# ESP32-P4 register map
Vendor: ESPRESSIF SYSTEMS (SHANGHAI) CO., LTD.; Series: ESP32 P-Series; File version: 3
CPU: RV32IMAFC r0p0, little endian, no MPU, FPU, 0 interrupt priority bits
Address unit: 32 bits
Registers are 32-bit, read-write, reset 0x0 unless marked. A register's access mark holds for its fields unless they carry their own. Offsets are from the block's base; [hi:lo] are bit positions; {n}, {i} and the like mark numbered series.

## PMU — PMU Peripheral
Base 0x50115000
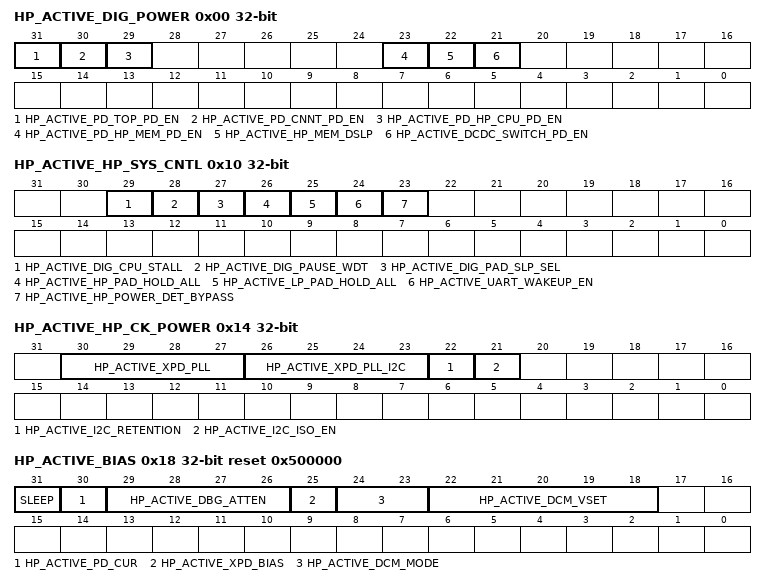
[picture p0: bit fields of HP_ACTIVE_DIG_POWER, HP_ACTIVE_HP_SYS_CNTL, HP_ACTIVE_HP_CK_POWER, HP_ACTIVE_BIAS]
0x00 HP_ACTIVE_DIG_POWER — need_des
  [31] HP_ACTIVE_PD_TOP_PD_EN — need_des
  [30] HP_ACTIVE_PD_CNNT_PD_EN — need_des
  [29] HP_ACTIVE_PD_HP_CPU_PD_EN — need_des
  [23] HP_ACTIVE_PD_HP_MEM_PD_EN — need_des
  [22] HP_ACTIVE_HP_MEM_DSLP — need_des
  [21] HP_ACTIVE_DCDC_SWITCH_PD_EN — need_des
0x04 HP_ACTIVE_ICG_HP_FUNC reset 0xFFFFFFFF — need_des
  [31:0] HP_ACTIVE_DIG_ICG_FUNC_EN
0x08 HP_ACTIVE_ICG_HP_APB reset 0xFFFFFFFF — need_des
  [31:0] HP_ACTIVE_DIG_ICG_APB_EN
0x0C HP_ACTIVE_ICG_MODEM — need_des
  [31:30] HP_ACTIVE_DIG_ICG_MODEM_CODE
0x10 HP_ACTIVE_HP_SYS_CNTL — need_des
  [29] HP_ACTIVE_DIG_CPU_STALL — need_des
  [28] HP_ACTIVE_DIG_PAUSE_WDT — need_des
  [27] HP_ACTIVE_DIG_PAD_SLP_SEL — need_des
  [26] HP_ACTIVE_HP_PAD_HOLD_ALL — need_des
  [25] HP_ACTIVE_LP_PAD_HOLD_ALL — need_des
  [24] HP_ACTIVE_UART_WAKEUP_EN — need_des
  [23] HP_ACTIVE_HP_POWER_DET_BYPASS — need_des
0x14 HP_ACTIVE_HP_CK_POWER — need_des
  [30:27] HP_ACTIVE_XPD_PLL — need_des
  [26:23] HP_ACTIVE_XPD_PLL_I2C — need_des
  [22] HP_ACTIVE_I2C_RETENTION — need_des
  [21] HP_ACTIVE_I2C_ISO_EN — need_des
0x18 HP_ACTIVE_BIAS reset 0x500000 — need_des
  [31] SLEEP — need_des
  [30] HP_ACTIVE_PD_CUR — need_des
  [29:26] HP_ACTIVE_DBG_ATTEN — need_des
  [25] HP_ACTIVE_XPD_BIAS — need_des
  [24:23] HP_ACTIVE_DCM_MODE — need_des
  [22:18] HP_ACTIVE_DCM_VSET — need_des
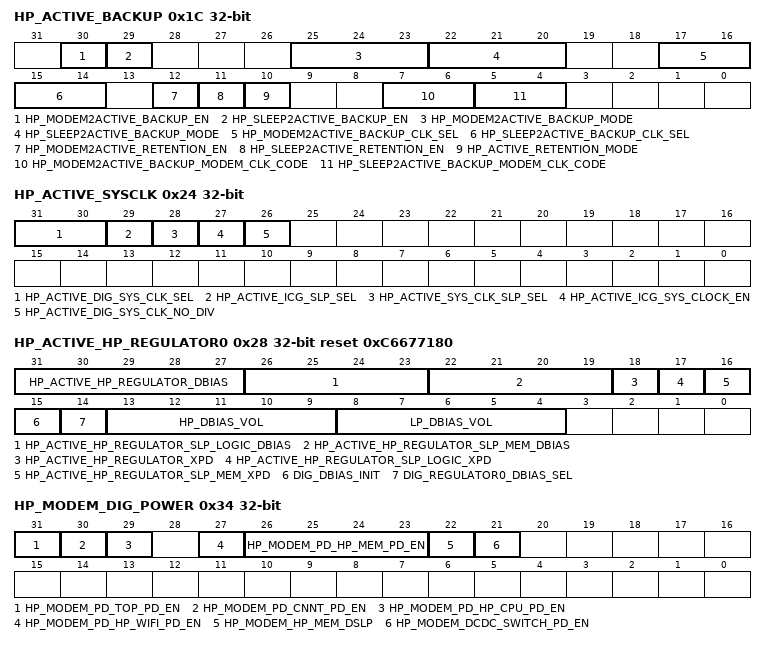
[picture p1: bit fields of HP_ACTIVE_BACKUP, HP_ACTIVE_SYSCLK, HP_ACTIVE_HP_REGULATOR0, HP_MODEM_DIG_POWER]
0x1C HP_ACTIVE_BACKUP — need_des
  [30] HP_MODEM2ACTIVE_BACKUP_EN — need_des
  [29] HP_SLEEP2ACTIVE_BACKUP_EN — need_des
  [25:23] HP_MODEM2ACTIVE_BACKUP_MODE — need_des
  [22:20] HP_SLEEP2ACTIVE_BACKUP_MODE — need_des
  [17:16] HP_MODEM2ACTIVE_BACKUP_CLK_SEL — need_des
  [15:14] HP_SLEEP2ACTIVE_BACKUP_CLK_SEL — need_des
  [12] HP_MODEM2ACTIVE_RETENTION_EN — need_des
  [11] HP_SLEEP2ACTIVE_RETENTION_EN — need_des
  [10] HP_ACTIVE_RETENTION_MODE — need_des
  [7:6] HP_MODEM2ACTIVE_BACKUP_MODEM_CLK_CODE — need_des
  [5:4] HP_SLEEP2ACTIVE_BACKUP_MODEM_CLK_CODE — need_des
0x20 HP_ACTIVE_BACKUP_CLK — need_des
  [31:0] HP_ACTIVE_BACKUP_ICG_FUNC_EN
0x24 HP_ACTIVE_SYSCLK — need_des
  [31:30] HP_ACTIVE_DIG_SYS_CLK_SEL — need_des
  [29] HP_ACTIVE_ICG_SLP_SEL — need_des
  [28] HP_ACTIVE_SYS_CLK_SLP_SEL — need_des
  [27] HP_ACTIVE_ICG_SYS_CLOCK_EN — need_des
  [26] HP_ACTIVE_DIG_SYS_CLK_NO_DIV — need_des
0x28 HP_ACTIVE_HP_REGULATOR0 access per field reset 0xC6677180 — need_des
  [31:27] HP_ACTIVE_HP_REGULATOR_DBIAS rw — need_des
  [26:23] HP_ACTIVE_HP_REGULATOR_SLP_LOGIC_DBIAS rw — need_des
  [22:19] HP_ACTIVE_HP_REGULATOR_SLP_MEM_DBIAS rw — need_des
  [18] HP_ACTIVE_HP_REGULATOR_XPD rw — need_des
  [17] HP_ACTIVE_HP_REGULATOR_SLP_LOGIC_XPD rw — need_des
  [16] HP_ACTIVE_HP_REGULATOR_SLP_MEM_XPD rw — need_des
  [15] DIG_DBIAS_INIT wo — need_des
  [14] DIG_REGULATOR0_DBIAS_SEL rw — need_des
  [13:9] HP_DBIAS_VOL ro — need_des
  [8:4] LP_DBIAS_VOL ro — need_des
0x2C HP_ACTIVE_HP_REGULATOR1 — need_des
  [31:26] HP_ACTIVE_HP_REGULATOR_DRV_B
0x30 HP_ACTIVE_XTAL reset 0x80000000 — need_des
  [31] HP_ACTIVE_XPD_XTAL
0x34 HP_MODEM_DIG_POWER access per field — need_des
  [31] HP_MODEM_PD_TOP_PD_EN wo — need_des
  [30] HP_MODEM_PD_CNNT_PD_EN wo — need_des
  [29] HP_MODEM_PD_HP_CPU_PD_EN wo — need_des
  [27] HP_MODEM_PD_HP_WIFI_PD_EN wo — need_des
  [26:23] HP_MODEM_PD_HP_MEM_PD_EN wo — need_des
  [22] HP_MODEM_HP_MEM_DSLP wo — need_des
  [21] HP_MODEM_DCDC_SWITCH_PD_EN rw — need_des
0x38 HP_MODEM_ICG_HP_FUNC wo — need_des
  [31:0] HP_MODEM_DIG_ICG_FUNC_EN
0x3C HP_MODEM_ICG_HP_APB wo — need_des
  [31:0] HP_MODEM_DIG_ICG_APB_EN
0x40 HP_MODEM_ICG_MODEM wo — need_des
  [31:30] HP_MODEM_DIG_ICG_MODEM_CODE
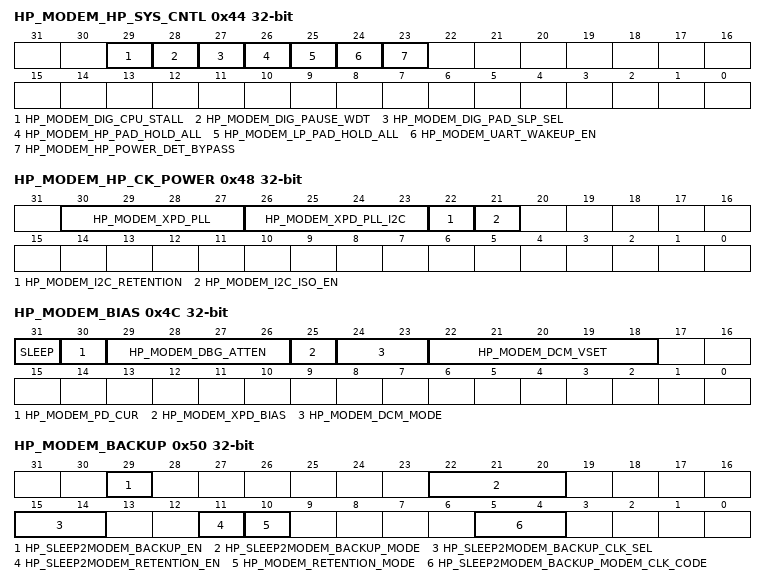
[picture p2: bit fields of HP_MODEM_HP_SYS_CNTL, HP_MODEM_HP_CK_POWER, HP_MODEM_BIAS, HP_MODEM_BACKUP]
0x44 HP_MODEM_HP_SYS_CNTL wo — need_des
  [29] HP_MODEM_DIG_CPU_STALL — need_des
  [28] HP_MODEM_DIG_PAUSE_WDT — need_des
  [27] HP_MODEM_DIG_PAD_SLP_SEL — need_des
  [26] HP_MODEM_HP_PAD_HOLD_ALL — need_des
  [25] HP_MODEM_LP_PAD_HOLD_ALL — need_des
  [24] HP_MODEM_UART_WAKEUP_EN — need_des
  [23] HP_MODEM_HP_POWER_DET_BYPASS — need_des
0x48 HP_MODEM_HP_CK_POWER wo — need_des
  [30:27] HP_MODEM_XPD_PLL — need_des
  [26:23] HP_MODEM_XPD_PLL_I2C — need_des
  [22] HP_MODEM_I2C_RETENTION — need_des
  [21] HP_MODEM_I2C_ISO_EN — need_des
0x4C HP_MODEM_BIAS wo — need_des
  [31] SLEEP — need_des
  [30] HP_MODEM_PD_CUR — need_des
  [29:26] HP_MODEM_DBG_ATTEN — need_des
  [25] HP_MODEM_XPD_BIAS — need_des
  [24:23] HP_MODEM_DCM_MODE — need_des
  [22:18] HP_MODEM_DCM_VSET — need_des
0x50 HP_MODEM_BACKUP wo — need_des
  [29] HP_SLEEP2MODEM_BACKUP_EN — need_des
  [22:20] HP_SLEEP2MODEM_BACKUP_MODE — need_des
  [15:14] HP_SLEEP2MODEM_BACKUP_CLK_SEL — need_des
  [11] HP_SLEEP2MODEM_RETENTION_EN — need_des
  [10] HP_MODEM_RETENTION_MODE — need_des
  [5:4] HP_SLEEP2MODEM_BACKUP_MODEM_CLK_CODE — need_des
0x54 HP_MODEM_BACKUP_CLK wo — need_des
  [31:0] HP_MODEM_BACKUP_ICG_FUNC_EN
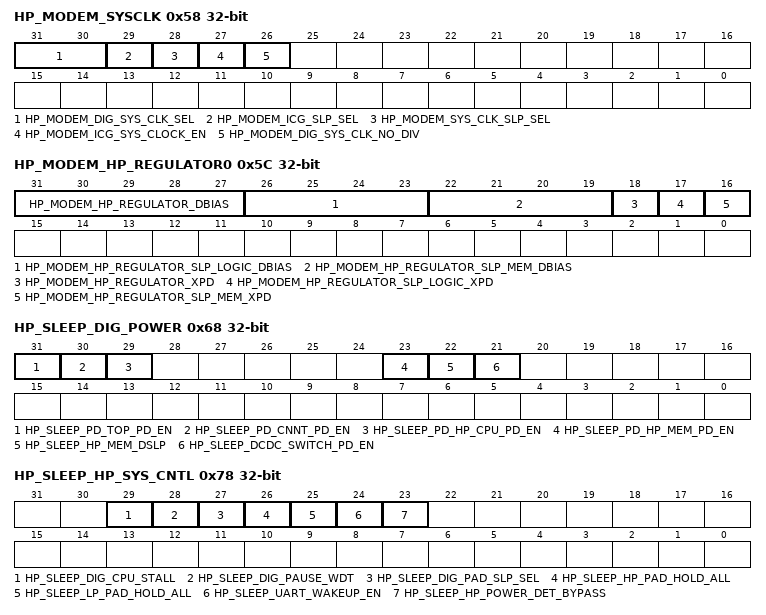
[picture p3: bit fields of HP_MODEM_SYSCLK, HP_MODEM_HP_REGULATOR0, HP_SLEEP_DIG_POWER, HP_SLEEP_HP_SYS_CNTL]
0x58 HP_MODEM_SYSCLK wo — need_des
  [31:30] HP_MODEM_DIG_SYS_CLK_SEL — need_des
  [29] HP_MODEM_ICG_SLP_SEL — need_des
  [28] HP_MODEM_SYS_CLK_SLP_SEL — need_des
  [27] HP_MODEM_ICG_SYS_CLOCK_EN — need_des
  [26] HP_MODEM_DIG_SYS_CLK_NO_DIV — need_des
0x5C HP_MODEM_HP_REGULATOR0 wo — need_des
  [31:27] HP_MODEM_HP_REGULATOR_DBIAS — need_des
  [26:23] HP_MODEM_HP_REGULATOR_SLP_LOGIC_DBIAS — need_des
  [22:19] HP_MODEM_HP_REGULATOR_SLP_MEM_DBIAS — need_des
  [18] HP_MODEM_HP_REGULATOR_XPD — need_des
  [17] HP_MODEM_HP_REGULATOR_SLP_LOGIC_XPD — need_des
  [16] HP_MODEM_HP_REGULATOR_SLP_MEM_XPD — need_des
0x60 HP_MODEM_HP_REGULATOR1 wo — need_des
  [31:8] HP_MODEM_HP_REGULATOR_DRV_B
0x64 HP_MODEM_XTAL wo — need_des
  [31] HP_MODEM_XPD_XTAL
0x68 HP_SLEEP_DIG_POWER — need_des
  [31] HP_SLEEP_PD_TOP_PD_EN — need_des
  [30] HP_SLEEP_PD_CNNT_PD_EN — need_des
  [29] HP_SLEEP_PD_HP_CPU_PD_EN — need_des
  [23] HP_SLEEP_PD_HP_MEM_PD_EN — need_des
  [22] HP_SLEEP_HP_MEM_DSLP — need_des
  [21] HP_SLEEP_DCDC_SWITCH_PD_EN — need_des
0x6C HP_SLEEP_ICG_HP_FUNC reset 0xFFFFFFFF — need_des
  [31:0] HP_SLEEP_DIG_ICG_FUNC_EN
0x70 HP_SLEEP_ICG_HP_APB reset 0xFFFFFFFF — need_des
  [31:0] HP_SLEEP_DIG_ICG_APB_EN
0x74 HP_SLEEP_ICG_MODEM — need_des
  [31:30] HP_SLEEP_DIG_ICG_MODEM_CODE
0x78 HP_SLEEP_HP_SYS_CNTL — need_des
  [29] HP_SLEEP_DIG_CPU_STALL — need_des
  [28] HP_SLEEP_DIG_PAUSE_WDT — need_des
  [27] HP_SLEEP_DIG_PAD_SLP_SEL — need_des
  [26] HP_SLEEP_HP_PAD_HOLD_ALL — need_des
  [25] HP_SLEEP_LP_PAD_HOLD_ALL — need_des
  [24] HP_SLEEP_UART_WAKEUP_EN — need_des
  [23] HP_SLEEP_HP_POWER_DET_BYPASS — need_des
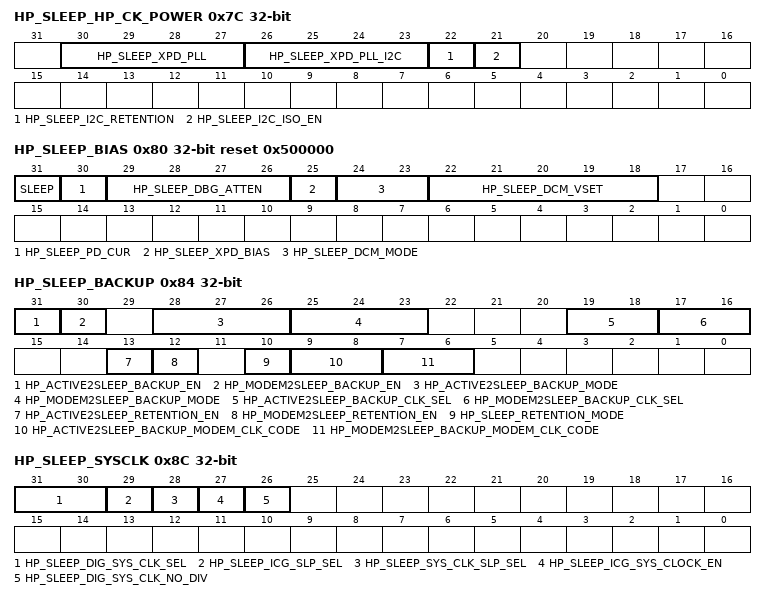
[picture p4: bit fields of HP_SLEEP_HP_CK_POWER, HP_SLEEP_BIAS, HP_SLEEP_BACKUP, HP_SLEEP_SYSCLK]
0x7C HP_SLEEP_HP_CK_POWER — need_des
  [30:27] HP_SLEEP_XPD_PLL — need_des
  [26:23] HP_SLEEP_XPD_PLL_I2C — need_des
  [22] HP_SLEEP_I2C_RETENTION — need_des
  [21] HP_SLEEP_I2C_ISO_EN — need_des
0x80 HP_SLEEP_BIAS reset 0x500000 — need_des
  [31] SLEEP — need_des
  [30] HP_SLEEP_PD_CUR — need_des
  [29:26] HP_SLEEP_DBG_ATTEN — need_des
  [25] HP_SLEEP_XPD_BIAS — need_des
  [24:23] HP_SLEEP_DCM_MODE — need_des
  [22:18] HP_SLEEP_DCM_VSET — need_des
0x84 HP_SLEEP_BACKUP — need_des
  [31] HP_ACTIVE2SLEEP_BACKUP_EN — need_des
  [30] HP_MODEM2SLEEP_BACKUP_EN — need_des
  [28:26] HP_ACTIVE2SLEEP_BACKUP_MODE — need_des
  [25:23] HP_MODEM2SLEEP_BACKUP_MODE — need_des
  [19:18] HP_ACTIVE2SLEEP_BACKUP_CLK_SEL — need_des
  [17:16] HP_MODEM2SLEEP_BACKUP_CLK_SEL — need_des
  [13] HP_ACTIVE2SLEEP_RETENTION_EN — need_des
  [12] HP_MODEM2SLEEP_RETENTION_EN — need_des
  [10] HP_SLEEP_RETENTION_MODE — need_des
  [9:8] HP_ACTIVE2SLEEP_BACKUP_MODEM_CLK_CODE — need_des
  [7:6] HP_MODEM2SLEEP_BACKUP_MODEM_CLK_CODE — need_des
0x88 HP_SLEEP_BACKUP_CLK — need_des
  [31:0] HP_SLEEP_BACKUP_ICG_FUNC_EN
0x8C HP_SLEEP_SYSCLK — need_des
  [31:30] HP_SLEEP_DIG_SYS_CLK_SEL — need_des
  [29] HP_SLEEP_ICG_SLP_SEL — need_des
  [28] HP_SLEEP_SYS_CLK_SLP_SEL — need_des
  [27] HP_SLEEP_ICG_SYS_CLOCK_EN — need_des
  [26] HP_SLEEP_DIG_SYS_CLK_NO_DIV — need_des
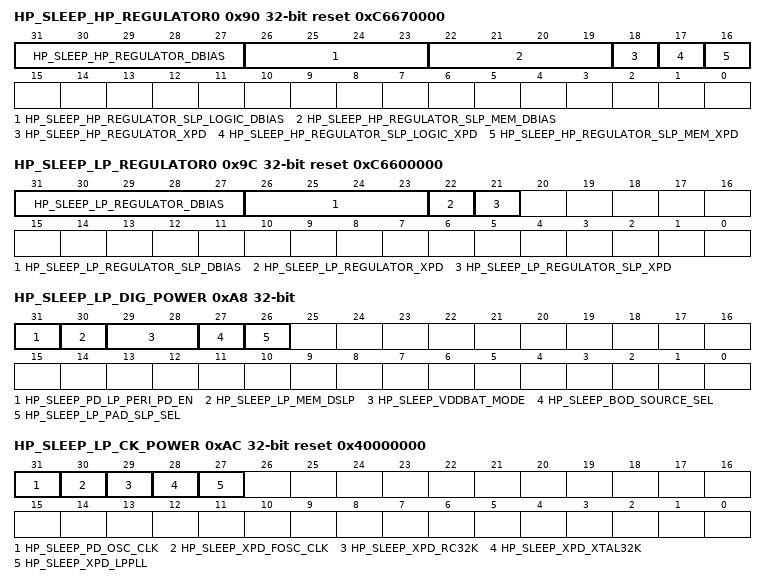
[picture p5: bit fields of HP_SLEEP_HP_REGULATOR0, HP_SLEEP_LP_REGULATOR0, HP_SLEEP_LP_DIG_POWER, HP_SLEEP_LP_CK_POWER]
0x90 HP_SLEEP_HP_REGULATOR0 reset 0xC6670000 — need_des
  [31:27] HP_SLEEP_HP_REGULATOR_DBIAS — need_des
  [26:23] HP_SLEEP_HP_REGULATOR_SLP_LOGIC_DBIAS — need_des
  [22:19] HP_SLEEP_HP_REGULATOR_SLP_MEM_DBIAS — need_des
  [18] HP_SLEEP_HP_REGULATOR_XPD — need_des
  [17] HP_SLEEP_HP_REGULATOR_SLP_LOGIC_XPD — need_des
  [16] HP_SLEEP_HP_REGULATOR_SLP_MEM_XPD — need_des
0x94 HP_SLEEP_HP_REGULATOR1 — need_des
  [31:26] HP_SLEEP_HP_REGULATOR_DRV_B
0x98 HP_SLEEP_XTAL reset 0x80000000 — need_des
  [31] HP_SLEEP_XPD_XTAL
0x9C HP_SLEEP_LP_REGULATOR0 reset 0xC6600000 — need_des
  [31:27] HP_SLEEP_LP_REGULATOR_DBIAS — need_des
  [26:23] HP_SLEEP_LP_REGULATOR_SLP_DBIAS — need_des
  [22] HP_SLEEP_LP_REGULATOR_XPD — need_des
  [21] HP_SLEEP_LP_REGULATOR_SLP_XPD — need_des
0xA0 HP_SLEEP_LP_REGULATOR1 — need_des
  [31:26] HP_SLEEP_LP_REGULATOR_DRV_B
0xA4 HP_SLEEP_LP_DCDC_RESERVE wo — need_des
  [31:0] PMU_HP_SLEEP_LP_DCDC_RESERVE
0xA8 HP_SLEEP_LP_DIG_POWER — need_des
  [31] HP_SLEEP_PD_LP_PERI_PD_EN — need_des
  [30] HP_SLEEP_LP_MEM_DSLP — need_des
  [29:28] HP_SLEEP_VDDBAT_MODE — need_des
  [27] HP_SLEEP_BOD_SOURCE_SEL — need_des
  [26] HP_SLEEP_LP_PAD_SLP_SEL — need_des
0xAC HP_SLEEP_LP_CK_POWER reset 0x40000000 — need_des
  [31] HP_SLEEP_PD_OSC_CLK — need_des
  [30] HP_SLEEP_XPD_FOSC_CLK — need_des
  [29] HP_SLEEP_XPD_RC32K — need_des
  [28] HP_SLEEP_XPD_XTAL32K — need_des
  [27] HP_SLEEP_XPD_LPPLL — need_des
0xB0 LP_SLEEP_LP_BIAS_RESERVE wo — need_des
  [31:0] PMU_LP_SLEEP_LP_BIAS_RESERVE
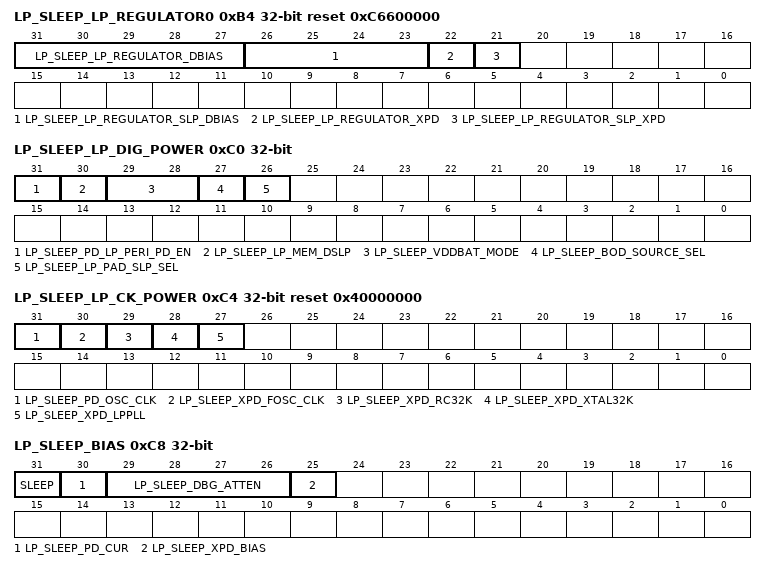
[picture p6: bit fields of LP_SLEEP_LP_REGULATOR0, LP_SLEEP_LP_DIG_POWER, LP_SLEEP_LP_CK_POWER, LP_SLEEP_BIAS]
0xB4 LP_SLEEP_LP_REGULATOR0 reset 0xC6600000 — need_des
  [31:27] LP_SLEEP_LP_REGULATOR_DBIAS — need_des
  [26:23] LP_SLEEP_LP_REGULATOR_SLP_DBIAS — need_des
  [22] LP_SLEEP_LP_REGULATOR_XPD — need_des
  [21] LP_SLEEP_LP_REGULATOR_SLP_XPD — need_des
0xB8 LP_SLEEP_LP_REGULATOR1 — need_des
  [31:26] LP_SLEEP_LP_REGULATOR_DRV_B
0xBC LP_SLEEP_XTAL reset 0x80000000 — need_des
  [31] LP_SLEEP_XPD_XTAL
0xC0 LP_SLEEP_LP_DIG_POWER — need_des
  [31] LP_SLEEP_PD_LP_PERI_PD_EN — need_des
  [30] LP_SLEEP_LP_MEM_DSLP — need_des
  [29:28] LP_SLEEP_VDDBAT_MODE — need_des
  [27] LP_SLEEP_BOD_SOURCE_SEL — need_des
  [26] LP_SLEEP_LP_PAD_SLP_SEL — need_des
0xC4 LP_SLEEP_LP_CK_POWER reset 0x40000000 — need_des
  [31] LP_SLEEP_PD_OSC_CLK — need_des
  [30] LP_SLEEP_XPD_FOSC_CLK — need_des
  [29] LP_SLEEP_XPD_RC32K — need_des
  [28] LP_SLEEP_XPD_XTAL32K — need_des
  [27] LP_SLEEP_XPD_LPPLL — need_des
0xC8 LP_SLEEP_BIAS — need_des
  [31] SLEEP — need_des
  [30] LP_SLEEP_PD_CUR — need_des
  [29:26] LP_SLEEP_DBG_ATTEN — need_des
  [25] LP_SLEEP_XPD_BIAS — need_des
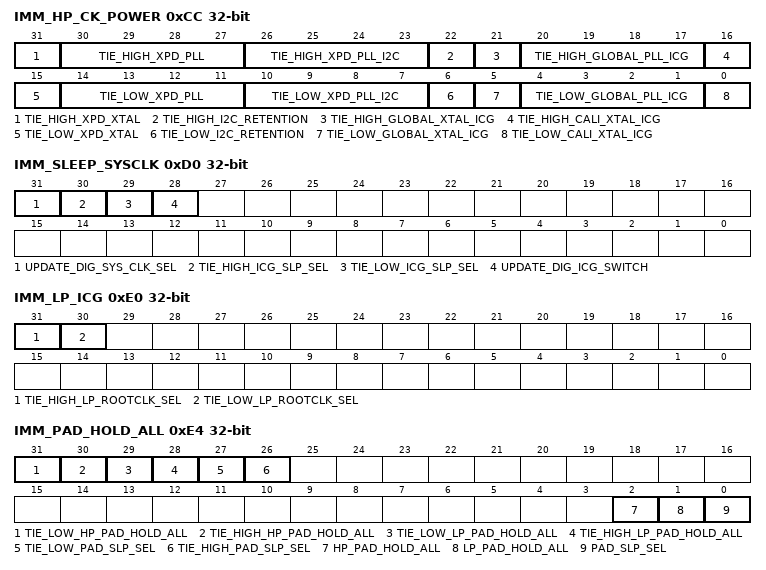
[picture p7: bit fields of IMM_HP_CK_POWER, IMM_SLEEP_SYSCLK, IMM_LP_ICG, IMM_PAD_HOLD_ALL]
0xCC IMM_HP_CK_POWER access per field — need_des
  [31] TIE_HIGH_XPD_XTAL wo — need_des
  [30:27] TIE_HIGH_XPD_PLL wo — need_des
  [26:23] TIE_HIGH_XPD_PLL_I2C wo — need_des
  [22] TIE_HIGH_I2C_RETENTION wo — need_des
  [21] TIE_HIGH_GLOBAL_XTAL_ICG wo — need_des
  [20:17] TIE_HIGH_GLOBAL_PLL_ICG wo — need_des
  [16] TIE_HIGH_CALI_XTAL_ICG rw — need_des
  [15] TIE_LOW_XPD_XTAL wo — need_des
  [14:11] TIE_LOW_XPD_PLL wo — need_des
  [10:7] TIE_LOW_XPD_PLL_I2C wo — need_des
  [6] TIE_LOW_I2C_RETENTION wo — need_des
  [5] TIE_LOW_GLOBAL_XTAL_ICG wo — need_des
  [4:1] TIE_LOW_GLOBAL_PLL_ICG wo — need_des
  [0] TIE_LOW_CALI_XTAL_ICG rw — need_des
0xD0 IMM_SLEEP_SYSCLK wo — need_des
  [31] UPDATE_DIG_SYS_CLK_SEL — need_des
  [30] TIE_HIGH_ICG_SLP_SEL — need_des
  [29] TIE_LOW_ICG_SLP_SEL — need_des
  [28] UPDATE_DIG_ICG_SWITCH — need_des
0xD4 IMM_HP_FUNC_ICG wo — need_des
  [31] UPDATE_DIG_ICG_FUNC_EN
0xD8 IMM_HP_APB_ICG wo — need_des
  [31] UPDATE_DIG_ICG_APB_EN
0xDC IMM_MODEM_ICG wo — need_des
  [31] UPDATE_DIG_ICG_MODEM_EN
0xE0 IMM_LP_ICG wo — need_des
  [31] TIE_HIGH_LP_ROOTCLK_SEL — need_des
  [30] TIE_LOW_LP_ROOTCLK_SEL — need_des
0xE4 IMM_PAD_HOLD_ALL access per field — need_des
  [31] TIE_LOW_HP_PAD_HOLD_ALL wo — need_des
  [30] TIE_HIGH_HP_PAD_HOLD_ALL wo — need_des
  [29] TIE_LOW_LP_PAD_HOLD_ALL wo — need_des
  [28] TIE_HIGH_LP_PAD_HOLD_ALL wo — need_des
  [27] TIE_LOW_PAD_SLP_SEL wo — need_des
  [26] TIE_HIGH_PAD_SLP_SEL wo — need_des
  [2] HP_PAD_HOLD_ALL ro — need_des
  [1] LP_PAD_HOLD_ALL ro — need_des
  [0] PAD_SLP_SEL ro — need_des
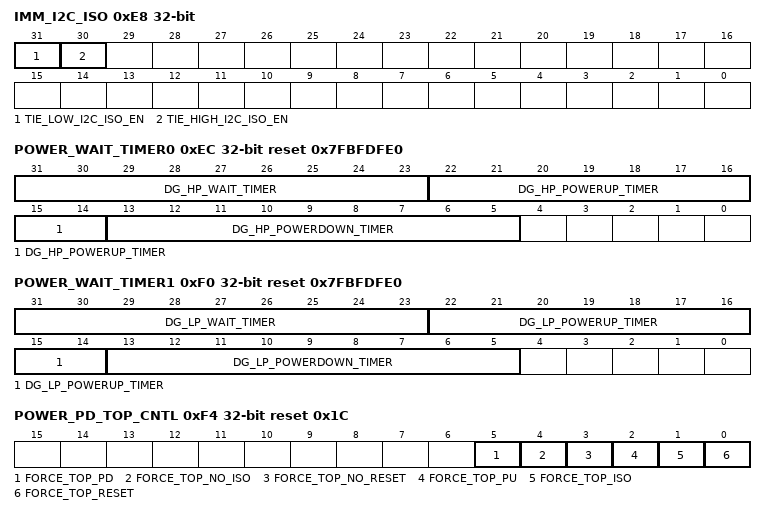
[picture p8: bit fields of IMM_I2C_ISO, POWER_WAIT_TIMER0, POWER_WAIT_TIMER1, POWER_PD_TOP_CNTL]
0xE8 IMM_I2C_ISO wo — need_des
  [31] TIE_LOW_I2C_ISO_EN — need_des
  [30] TIE_HIGH_I2C_ISO_EN — need_des
0xEC POWER_WAIT_TIMER0 reset 0x7FBFDFE0 — need_des
  [31:23] DG_HP_WAIT_TIMER — need_des
  [22:14] DG_HP_POWERUP_TIMER — need_des
  [13:5] DG_HP_POWERDOWN_TIMER — need_des
0xF0 POWER_WAIT_TIMER1 reset 0x7FBFDFE0 — need_des
  [31:23] DG_LP_WAIT_TIMER — need_des
  [22:14] DG_LP_POWERUP_TIMER — need_des
  [13:5] DG_LP_POWERDOWN_TIMER — need_des
0xF4 POWER_PD_TOP_CNTL reset 0x1C — need_des
  [5] FORCE_TOP_PD — need_des
  [4] FORCE_TOP_NO_ISO — need_des
  [3] FORCE_TOP_NO_RESET — need_des
  [2] FORCE_TOP_PU — need_des
  [1] FORCE_TOP_ISO — need_des
  [0] FORCE_TOP_RESET — need_des
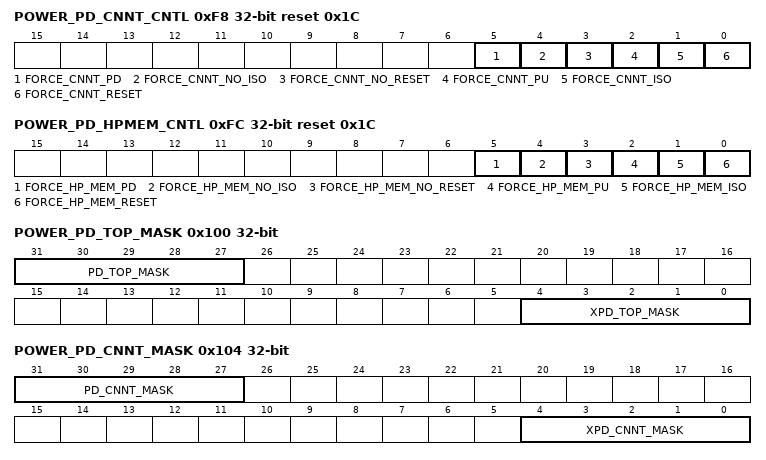
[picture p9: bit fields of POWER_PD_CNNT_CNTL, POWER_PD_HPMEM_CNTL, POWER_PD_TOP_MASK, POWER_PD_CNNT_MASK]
0xF8 POWER_PD_CNNT_CNTL reset 0x1C — need_des
  [5] FORCE_CNNT_PD — need_des
  [4] FORCE_CNNT_NO_ISO — need_des
  [3] FORCE_CNNT_NO_RESET — need_des
  [2] FORCE_CNNT_PU — need_des
  [1] FORCE_CNNT_ISO — need_des
  [0] FORCE_CNNT_RESET — need_des
0xFC POWER_PD_HPMEM_CNTL reset 0x1C — need_des
  [5] FORCE_HP_MEM_PD — need_des
  [4] FORCE_HP_MEM_NO_ISO — need_des
  [3] FORCE_HP_MEM_NO_RESET — need_des
  [2] FORCE_HP_MEM_PU — need_des
  [1] FORCE_HP_MEM_ISO — need_des
  [0] FORCE_HP_MEM_RESET — need_des
0x100 POWER_PD_TOP_MASK — need_des
  [31:27] PD_TOP_MASK — need_des
  [4:0] XPD_TOP_MASK — need_des
0x104 POWER_PD_CNNT_MASK — need_des
  [31:27] PD_CNNT_MASK — need_des
  [4:0] XPD_CNNT_MASK — need_des
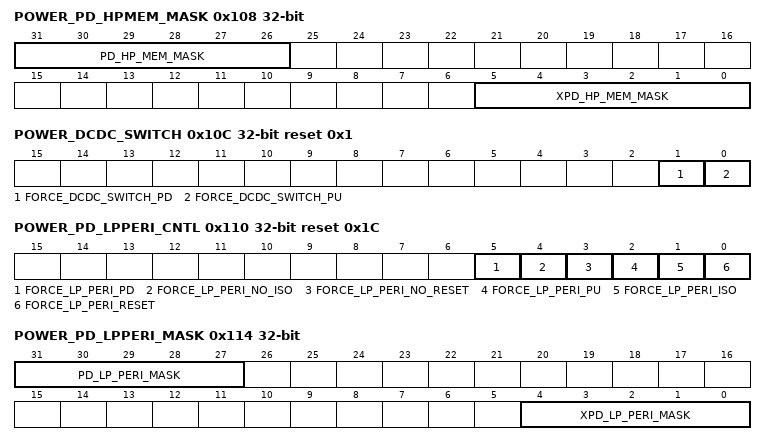
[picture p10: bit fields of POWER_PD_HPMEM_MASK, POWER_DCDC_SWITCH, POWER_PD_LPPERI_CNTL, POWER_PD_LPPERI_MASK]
0x108 POWER_PD_HPMEM_MASK — need_des
  [31:26] PD_HP_MEM_MASK — need_des
  [5:0] XPD_HP_MEM_MASK — need_des
0x10C POWER_DCDC_SWITCH reset 0x1 — need_des
  [1] FORCE_DCDC_SWITCH_PD — need_des
  [0] FORCE_DCDC_SWITCH_PU — need_des
0x110 POWER_PD_LPPERI_CNTL reset 0x1C — need_des
  [5] FORCE_LP_PERI_PD — need_des
  [4] FORCE_LP_PERI_NO_ISO — need_des
  [3] FORCE_LP_PERI_NO_RESET — need_des
  [2] FORCE_LP_PERI_PU — need_des
  [1] FORCE_LP_PERI_ISO — need_des
  [0] FORCE_LP_PERI_RESET — need_des
0x114 POWER_PD_LPPERI_MASK — need_des
  [31:27] PD_LP_PERI_MASK — need_des
  [4:0] XPD_LP_PERI_MASK — need_des
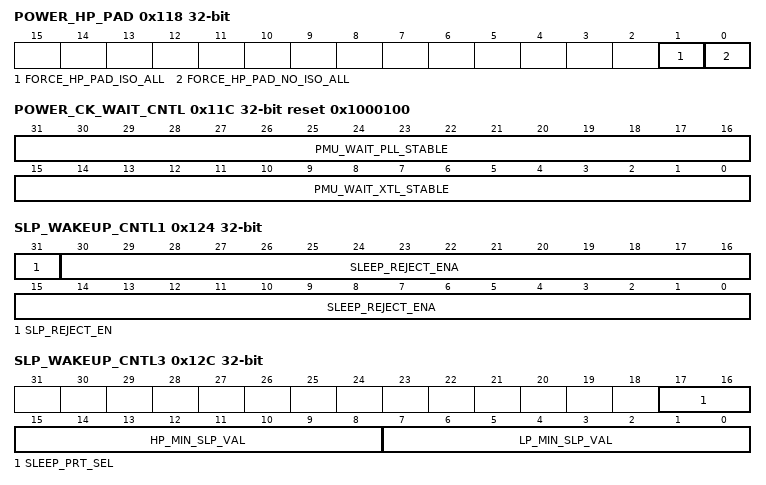
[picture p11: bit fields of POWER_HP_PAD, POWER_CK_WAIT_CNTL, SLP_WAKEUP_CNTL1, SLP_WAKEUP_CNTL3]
0x118 POWER_HP_PAD — need_des
  [1] FORCE_HP_PAD_ISO_ALL — need_des
  [0] FORCE_HP_PAD_NO_ISO_ALL — need_des
0x11C POWER_CK_WAIT_CNTL reset 0x1000100 — need_des
  [31:16] PMU_WAIT_PLL_STABLE — need_des
  [15:0] PMU_WAIT_XTL_STABLE — need_des
0x120 SLP_WAKEUP_CNTL0 wo — need_des
  [31] SLEEP_REQ
0x124 SLP_WAKEUP_CNTL1 — need_des
  [31] SLP_REJECT_EN — need_des
  [30:0] SLEEP_REJECT_ENA — need_des
0x128 SLP_WAKEUP_CNTL2 — need_des
  [30:0] WAKEUP_ENA
0x12C SLP_WAKEUP_CNTL3 — need_des
  [17:16] SLEEP_PRT_SEL — need_des
  [15:8] HP_MIN_SLP_VAL — need_des
  [7:0] LP_MIN_SLP_VAL — need_des
0x130 SLP_WAKEUP_CNTL4 wo — need_des
  [31] SLP_REJECT_CAUSE_CLR
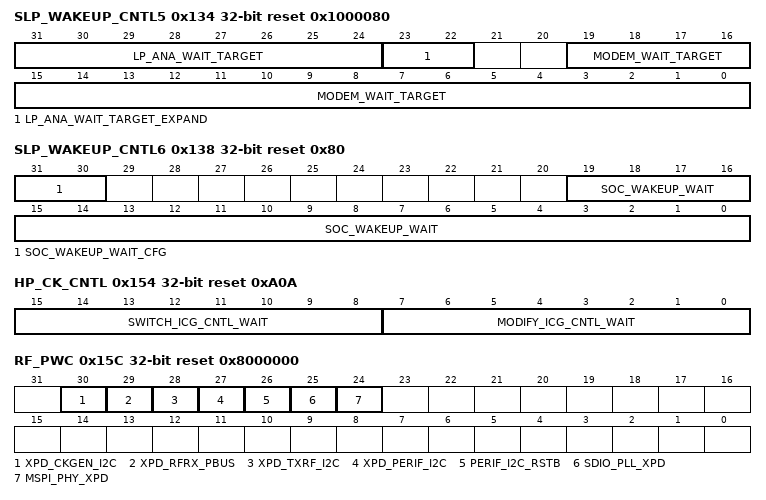
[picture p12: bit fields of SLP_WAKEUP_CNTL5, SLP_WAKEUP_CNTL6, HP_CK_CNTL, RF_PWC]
0x134 SLP_WAKEUP_CNTL5 reset 0x1000080 — need_des
  [31:24] LP_ANA_WAIT_TARGET — need_des
  [23:22] LP_ANA_WAIT_TARGET_EXPAND — need_des
  [19:0] MODEM_WAIT_TARGET — need_des
0x138 SLP_WAKEUP_CNTL6 reset 0x80 — need_des
  [31:30] SOC_WAKEUP_WAIT_CFG — need_des
  [19:0] SOC_WAKEUP_WAIT — need_des
0x13C SLP_WAKEUP_CNTL7 reset 0x10000 — need_des
  [31:16] ANA_WAIT_TARGET
0x140 SLP_WAKEUP_CNTL8 — need_des
  [31] LP_LITE_WAKEUP_ENA
0x144 SLP_WAKEUP_STATUS0 ro — need_des
  [30:0] WAKEUP_CAUSE
0x148 SLP_WAKEUP_STATUS1 ro — need_des
  [30:0] REJECT_CAUSE
0x14C SLP_WAKEUP_STATUS2 ro — need_des
  [31] LP_LITE_WAKEUP_CAUSE
0x150 HP_CK_POWERON reset 0x32 — need_des
  [7:0] I2C_POR_WAIT_TARGET
0x154 HP_CK_CNTL reset 0xA0A — need_des
  [15:8] SWITCH_ICG_CNTL_WAIT — need_des
  [7:0] MODIFY_ICG_CNTL_WAIT — need_des
0x158 POR_STATUS ro — need_des
  [31] POR_DONE
0x15C RF_PWC reset 0x8000000 — need_des
  [30] XPD_CKGEN_I2C — need_des
  [29] XPD_RFRX_PBUS — need_des
  [28] XPD_TXRF_I2C — need_des
  [27] XPD_PERIF_I2C — need_des
  [26] PERIF_I2C_RSTB — need_des
  [25] SDIO_PLL_XPD — need_des
  [24] MSPI_PHY_XPD — need_des
0x160 BACKUP_CFG reset 0x80000000 — need_des
  [31] BACKUP_SYS_CLK_NO_DIV
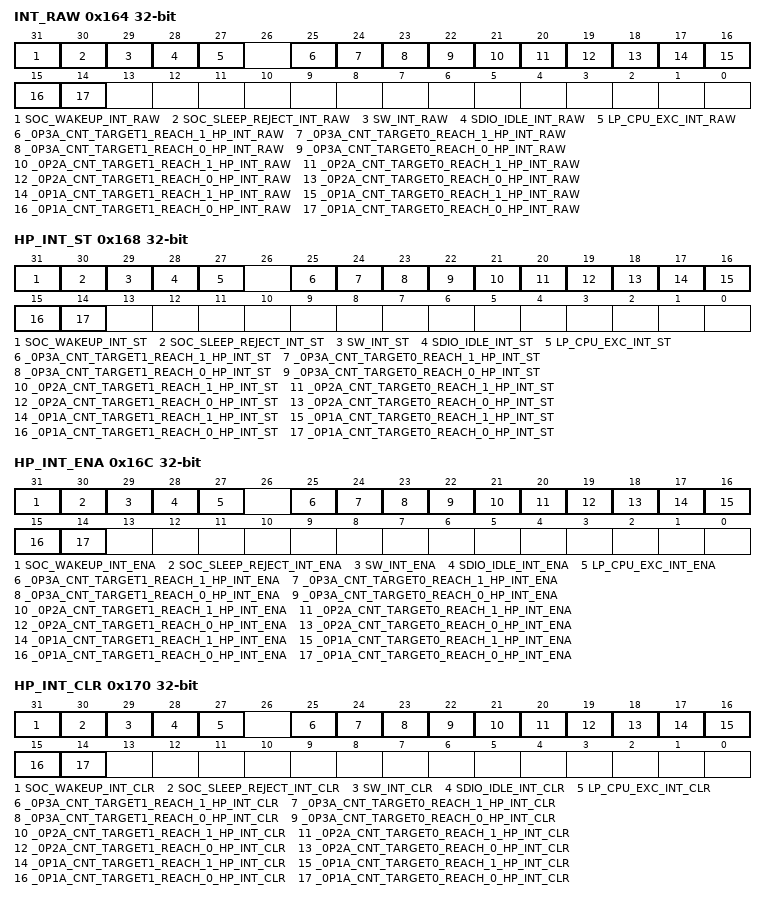
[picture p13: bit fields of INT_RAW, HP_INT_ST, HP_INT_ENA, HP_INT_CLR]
0x164 INT_RAW — need_des
  [31] SOC_WAKEUP_INT_RAW — need_des
  [30] SOC_SLEEP_REJECT_INT_RAW — need_des
  [29] SW_INT_RAW — need_des
  [28] SDIO_IDLE_INT_RAW — need_des
  [27] LP_CPU_EXC_INT_RAW — need_des
  [25] _0P3A_CNT_TARGET1_REACH_1_HP_INT_RAW — reg_0p3a_1_counter after xpd reach target1
  [24] _0P3A_CNT_TARGET0_REACH_1_HP_INT_RAW — reg_0p3a_0_counter after xpd reach target0
  [23] _0P3A_CNT_TARGET1_REACH_0_HP_INT_RAW — reg_0p3a_1_counter after xpd reach target1
  [22] _0P3A_CNT_TARGET0_REACH_0_HP_INT_RAW — reg_0p3a_0 counter after xpd reach target0
  [21] _0P2A_CNT_TARGET1_REACH_1_HP_INT_RAW — reg_0p2a_1_counter after xpd reach target1
  [20] _0P2A_CNT_TARGET0_REACH_1_HP_INT_RAW — reg_0p2a_0 counter after xpd reach target0
  [19] _0P2A_CNT_TARGET1_REACH_0_HP_INT_RAW — reg_0p2a_1_counter after xpd reach target1
  [18] _0P2A_CNT_TARGET0_REACH_0_HP_INT_RAW — reg_0p2a_0 counter after xpd reach target0
  [17] _0P1A_CNT_TARGET1_REACH_1_HP_INT_RAW — reg_0p1a_1_counter after xpd reach target1
  [16] _0P1A_CNT_TARGET0_REACH_1_HP_INT_RAW — reg_0p1a_0 counter after xpd reach target0
  [15] _0P1A_CNT_TARGET1_REACH_0_HP_INT_RAW — reg_0p1a_1_counter after xpd reach target1
  [14] _0P1A_CNT_TARGET0_REACH_0_HP_INT_RAW — reg_0p1a_0_counter after xpd reach target0
0x168 HP_INT_ST ro — need_des
  [31] SOC_WAKEUP_INT_ST — need_des
  [30] SOC_SLEEP_REJECT_INT_ST — need_des
  [29] SW_INT_ST — need_des
  [28] SDIO_IDLE_INT_ST — need_des
  [27] LP_CPU_EXC_INT_ST — need_des
  [25] _0P3A_CNT_TARGET1_REACH_1_HP_INT_ST — reg_0p3a_1_counter after xpd reach target1
  [24] _0P3A_CNT_TARGET0_REACH_1_HP_INT_ST — reg_0p3a_0_counter after xpd reach target0
  [23] _0P3A_CNT_TARGET1_REACH_0_HP_INT_ST — reg_0p3a_1_counter after xpd reach target1
  [22] _0P3A_CNT_TARGET0_REACH_0_HP_INT_ST — reg_0p3a_0 counter after xpd reach target0
  [21] _0P2A_CNT_TARGET1_REACH_1_HP_INT_ST — reg_0p2a_1_counter after xpd reach target1
  [20] _0P2A_CNT_TARGET0_REACH_1_HP_INT_ST — reg_0p2a_0 counter after xpd reach target0
  [19] _0P2A_CNT_TARGET1_REACH_0_HP_INT_ST — reg_0p2a_1_counter after xpd reach target1
  [18] _0P2A_CNT_TARGET0_REACH_0_HP_INT_ST — reg_0p2a_0 counter after xpd reach target0
  [17] _0P1A_CNT_TARGET1_REACH_1_HP_INT_ST — reg_0p1a_1_counter after xpd reach target1
  [16] _0P1A_CNT_TARGET0_REACH_1_HP_INT_ST — reg_0p1a_0 counter after xpd reach target0
  [15] _0P1A_CNT_TARGET1_REACH_0_HP_INT_ST — reg_0p1a_1_counter after xpd reach target1
  [14] _0P1A_CNT_TARGET0_REACH_0_HP_INT_ST — reg_0p1a_0_counter after xpd reach target0
0x16C HP_INT_ENA — need_des
  [31] SOC_WAKEUP_INT_ENA — need_des
  [30] SOC_SLEEP_REJECT_INT_ENA — need_des
  [29] SW_INT_ENA — need_des
  [28] SDIO_IDLE_INT_ENA — need_des
  [27] LP_CPU_EXC_INT_ENA — need_des
  [25] _0P3A_CNT_TARGET1_REACH_1_HP_INT_ENA — reg_0p3a_1_counter after xpd reach target1
  [24] _0P3A_CNT_TARGET0_REACH_1_HP_INT_ENA — reg_0p3a_0_counter after xpd reach target0
  [23] _0P3A_CNT_TARGET1_REACH_0_HP_INT_ENA — reg_0p3a_1_counter after xpd reach target1
  [22] _0P3A_CNT_TARGET0_REACH_0_HP_INT_ENA — reg_0p3a_0 counter after xpd reach target0
  [21] _0P2A_CNT_TARGET1_REACH_1_HP_INT_ENA — reg_0p2a_1_counter after xpd reach target1
  [20] _0P2A_CNT_TARGET0_REACH_1_HP_INT_ENA — reg_0p2a_0 counter after xpd reach target0
  [19] _0P2A_CNT_TARGET1_REACH_0_HP_INT_ENA — reg_0p2a_1_counter after xpd reach target1
  [18] _0P2A_CNT_TARGET0_REACH_0_HP_INT_ENA — reg_0p2a_0 counter after xpd reach target0
  [17] _0P1A_CNT_TARGET1_REACH_1_HP_INT_ENA — reg_0p1a_1_counter after xpd reach target1
  [16] _0P1A_CNT_TARGET0_REACH_1_HP_INT_ENA — reg_0p1a_0 counter after xpd reach target0
  [15] _0P1A_CNT_TARGET1_REACH_0_HP_INT_ENA — reg_0p1a_1_counter after xpd reach target1
  [14] _0P1A_CNT_TARGET0_REACH_0_HP_INT_ENA — reg_0p1a_0_counter after xpd reach target0
0x170 HP_INT_CLR wo — need_des
  [31] SOC_WAKEUP_INT_CLR — need_des
  [30] SOC_SLEEP_REJECT_INT_CLR — need_des
  [29] SW_INT_CLR — need_des
  [28] SDIO_IDLE_INT_CLR — need_des
  [27] LP_CPU_EXC_INT_CLR — need_des
  [25] _0P3A_CNT_TARGET1_REACH_1_HP_INT_CLR — reg_0p3a_1_counter after xpd reach target1
  [24] _0P3A_CNT_TARGET0_REACH_1_HP_INT_CLR — reg_0p3a_0_counter after xpd reach target0
  [23] _0P3A_CNT_TARGET1_REACH_0_HP_INT_CLR — reg_0p3a_1_counter after xpd reach target1
  [22] _0P3A_CNT_TARGET0_REACH_0_HP_INT_CLR — reg_0p3a_0 counter after xpd reach target0
  [21] _0P2A_CNT_TARGET1_REACH_1_HP_INT_CLR — reg_0p2a_1_counter after xpd reach target1
  [20] _0P2A_CNT_TARGET0_REACH_1_HP_INT_CLR — reg_0p2a_0 counter after xpd reach target0
  [19] _0P2A_CNT_TARGET1_REACH_0_HP_INT_CLR — reg_0p2a_1_counter after xpd reach target1
  [18] _0P2A_CNT_TARGET0_REACH_0_HP_INT_CLR — reg_0p2a_0 counter after xpd reach target0
  [17] _0P1A_CNT_TARGET1_REACH_1_HP_INT_CLR — reg_0p1a_1_counter after xpd reach target1
  [16] _0P1A_CNT_TARGET0_REACH_1_HP_INT_CLR — reg_0p1a_0 counter after xpd reach target0
  [15] _0P1A_CNT_TARGET1_REACH_0_HP_INT_CLR — reg_0p1a_1_counter after xpd reach target1
  [14] _0P1A_CNT_TARGET0_REACH_0_HP_INT_CLR — reg_0p1a_0_counter after xpd reach target0
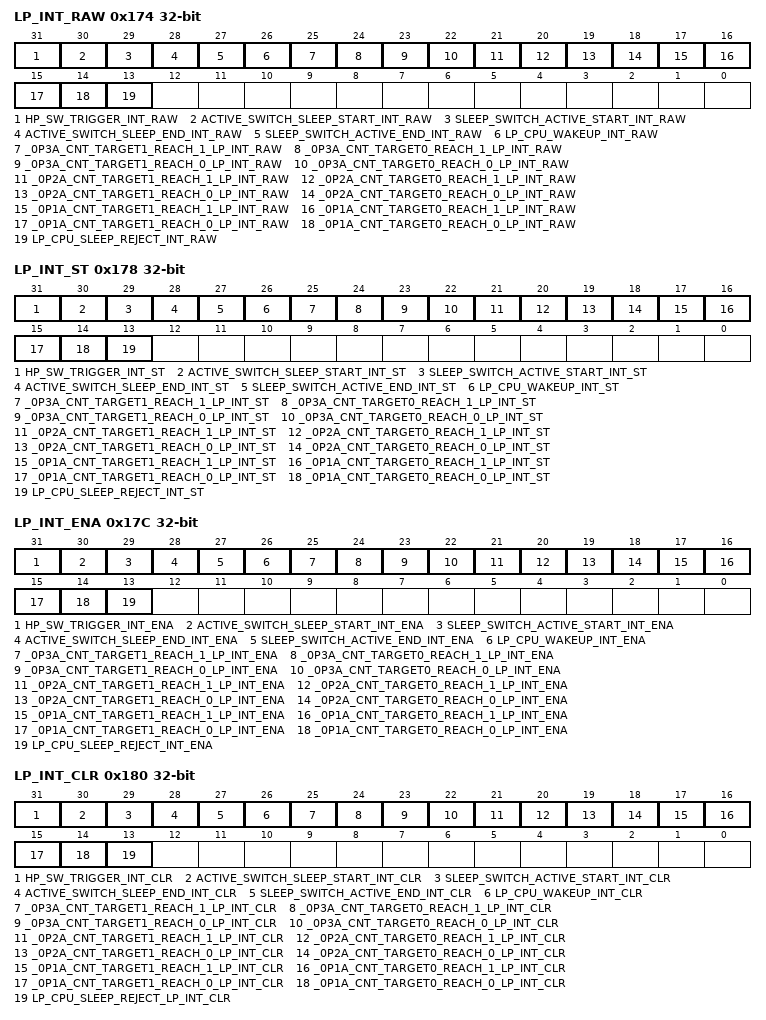
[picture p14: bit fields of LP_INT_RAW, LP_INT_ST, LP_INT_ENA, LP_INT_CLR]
0x174 LP_INT_RAW — need_des
  [31] HP_SW_TRIGGER_INT_RAW — need_des
  [30] ACTIVE_SWITCH_SLEEP_START_INT_RAW — need_des
  [29] SLEEP_SWITCH_ACTIVE_START_INT_RAW — need_des
  [28] ACTIVE_SWITCH_SLEEP_END_INT_RAW — need_des
  [27] SLEEP_SWITCH_ACTIVE_END_INT_RAW — need_des
  [26] LP_CPU_WAKEUP_INT_RAW — need_des
  [25] _0P3A_CNT_TARGET1_REACH_1_LP_INT_RAW — reg_0p3a_1_counter after xpd reach target1
  [24] _0P3A_CNT_TARGET0_REACH_1_LP_INT_RAW — reg_0p3a_0_counter after xpd reach target0
  [23] _0P3A_CNT_TARGET1_REACH_0_LP_INT_RAW — reg_0p3a_1_counter after xpd reach target1
  [22] _0P3A_CNT_TARGET0_REACH_0_LP_INT_RAW — reg_0p3a_0 counter after xpd reach target0
  [21] _0P2A_CNT_TARGET1_REACH_1_LP_INT_RAW — reg_0p2a_1_counter after xpd reach target1
  [20] _0P2A_CNT_TARGET0_REACH_1_LP_INT_RAW — reg_0p2a_0 counter after xpd reach target0
  [19] _0P2A_CNT_TARGET1_REACH_0_LP_INT_RAW — reg_0p2a_1_counter after xpd reach target1
  [18] _0P2A_CNT_TARGET0_REACH_0_LP_INT_RAW — reg_0p2a_0 counter after xpd reach target0
  [17] _0P1A_CNT_TARGET1_REACH_1_LP_INT_RAW — reg_0p1a_1_counter after xpd reach target1
  [16] _0P1A_CNT_TARGET0_REACH_1_LP_INT_RAW — reg_0p1a_0 counter after xpd reach target0
  [15] _0P1A_CNT_TARGET1_REACH_0_LP_INT_RAW — reg_0p1a_1_counter after xpd reach target1
  [14] _0P1A_CNT_TARGET0_REACH_0_LP_INT_RAW — reg_0p1a_0_counter after xpd reach target0
  [13] LP_CPU_SLEEP_REJECT_INT_RAW — need_des
0x178 LP_INT_ST ro — need_des
  [31] HP_SW_TRIGGER_INT_ST — need_des
  [30] ACTIVE_SWITCH_SLEEP_START_INT_ST — need_des
  [29] SLEEP_SWITCH_ACTIVE_START_INT_ST — need_des
  [28] ACTIVE_SWITCH_SLEEP_END_INT_ST — need_des
  [27] SLEEP_SWITCH_ACTIVE_END_INT_ST — need_des
  [26] LP_CPU_WAKEUP_INT_ST — need_des
  [25] _0P3A_CNT_TARGET1_REACH_1_LP_INT_ST — reg_0p3a_1_counter after xpd reach target1
  [24] _0P3A_CNT_TARGET0_REACH_1_LP_INT_ST — reg_0p3a_0_counter after xpd reach target0
  [23] _0P3A_CNT_TARGET1_REACH_0_LP_INT_ST — reg_0p3a_1_counter after xpd reach target1
  [22] _0P3A_CNT_TARGET0_REACH_0_LP_INT_ST — reg_0p3a_0 counter after xpd reach target0
  [21] _0P2A_CNT_TARGET1_REACH_1_LP_INT_ST — reg_0p2a_1_counter after xpd reach target1
  [20] _0P2A_CNT_TARGET0_REACH_1_LP_INT_ST — reg_0p2a_0 counter after xpd reach target0
  [19] _0P2A_CNT_TARGET1_REACH_0_LP_INT_ST — reg_0p2a_1_counter after xpd reach target1
  [18] _0P2A_CNT_TARGET0_REACH_0_LP_INT_ST — reg_0p2a_0 counter after xpd reach target0
  [17] _0P1A_CNT_TARGET1_REACH_1_LP_INT_ST — reg_0p1a_1_counter after xpd reach target1
  [16] _0P1A_CNT_TARGET0_REACH_1_LP_INT_ST — reg_0p1a_0 counter after xpd reach target0
  [15] _0P1A_CNT_TARGET1_REACH_0_LP_INT_ST — reg_0p1a_1_counter after xpd reach target1
  [14] _0P1A_CNT_TARGET0_REACH_0_LP_INT_ST — reg_0p1a_0_counter after xpd reach target0
  [13] LP_CPU_SLEEP_REJECT_INT_ST — need_des
0x17C LP_INT_ENA — need_des
  [31] HP_SW_TRIGGER_INT_ENA — need_des
  [30] ACTIVE_SWITCH_SLEEP_START_INT_ENA — need_des
  [29] SLEEP_SWITCH_ACTIVE_START_INT_ENA — need_des
  [28] ACTIVE_SWITCH_SLEEP_END_INT_ENA — need_des
  [27] SLEEP_SWITCH_ACTIVE_END_INT_ENA — need_des
  [26] LP_CPU_WAKEUP_INT_ENA — need_des
  [25] _0P3A_CNT_TARGET1_REACH_1_LP_INT_ENA — reg_0p3a_1_counter after xpd reach target1
  [24] _0P3A_CNT_TARGET0_REACH_1_LP_INT_ENA — reg_0p3a_0_counter after xpd reach target0
  [23] _0P3A_CNT_TARGET1_REACH_0_LP_INT_ENA — reg_0p3a_1_counter after xpd reach target1
  [22] _0P3A_CNT_TARGET0_REACH_0_LP_INT_ENA — reg_0p3a_0 counter after xpd reach target0
  [21] _0P2A_CNT_TARGET1_REACH_1_LP_INT_ENA — reg_0p2a_1_counter after xpd reach target1
  [20] _0P2A_CNT_TARGET0_REACH_1_LP_INT_ENA — reg_0p2a_0 counter after xpd reach target0
  [19] _0P2A_CNT_TARGET1_REACH_0_LP_INT_ENA — reg_0p2a_1_counter after xpd reach target1
  [18] _0P2A_CNT_TARGET0_REACH_0_LP_INT_ENA — reg_0p2a_0 counter after xpd reach target0
  [17] _0P1A_CNT_TARGET1_REACH_1_LP_INT_ENA — reg_0p1a_1_counter after xpd reach target1
  [16] _0P1A_CNT_TARGET0_REACH_1_LP_INT_ENA — reg_0p1a_0 counter after xpd reach target0
  [15] _0P1A_CNT_TARGET1_REACH_0_LP_INT_ENA — reg_0p1a_1_counter after xpd reach target1
  [14] _0P1A_CNT_TARGET0_REACH_0_LP_INT_ENA — reg_0p1a_0_counter after xpd reach target0
  [13] LP_CPU_SLEEP_REJECT_INT_ENA — need_des
0x180 LP_INT_CLR wo — need_des
  [31] HP_SW_TRIGGER_INT_CLR — need_des
  [30] ACTIVE_SWITCH_SLEEP_START_INT_CLR — need_des
  [29] SLEEP_SWITCH_ACTIVE_START_INT_CLR — need_des
  [28] ACTIVE_SWITCH_SLEEP_END_INT_CLR — need_des
  [27] SLEEP_SWITCH_ACTIVE_END_INT_CLR — need_des
  [26] LP_CPU_WAKEUP_INT_CLR — need_des
  [25] _0P3A_CNT_TARGET1_REACH_1_LP_INT_CLR — reg_0p3a_1_counter after xpd reach target1
  [24] _0P3A_CNT_TARGET0_REACH_1_LP_INT_CLR — reg_0p3a_0_counter after xpd reach target0
  [23] _0P3A_CNT_TARGET1_REACH_0_LP_INT_CLR — reg_0p3a_1_counter after xpd reach target1
  [22] _0P3A_CNT_TARGET0_REACH_0_LP_INT_CLR — reg_0p3a_0 counter after xpd reach target0
  [21] _0P2A_CNT_TARGET1_REACH_1_LP_INT_CLR — reg_0p2a_1_counter after xpd reach target1
  [20] _0P2A_CNT_TARGET0_REACH_1_LP_INT_CLR — reg_0p2a_0 counter after xpd reach target0
  [19] _0P2A_CNT_TARGET1_REACH_0_LP_INT_CLR — reg_0p2a_1_counter after xpd reach target1
  [18] _0P2A_CNT_TARGET0_REACH_0_LP_INT_CLR — reg_0p2a_0 counter after xpd reach target0
  [17] _0P1A_CNT_TARGET1_REACH_1_LP_INT_CLR — reg_0p1a_1_counter after xpd reach target1
  [16] _0P1A_CNT_TARGET0_REACH_1_LP_INT_CLR — reg_0p1a_0 counter after xpd reach target0
  [15] _0P1A_CNT_TARGET1_REACH_0_LP_INT_CLR — reg_0p1a_1_counter after xpd reach target1
  [14] _0P1A_CNT_TARGET0_REACH_0_LP_INT_CLR — reg_0p1a_0_counter after xpd reach target0
  [13] LP_CPU_SLEEP_REJECT_LP_INT_CLR — need_des
0x184 LP_CPU_PWR0 access per field reset 0x1FF00000 — need_des
  [31] LP_CPU_SLP_BYPASS_INTR_EN rw — need_des
  [30] LP_CPU_SLP_RESET_EN rw — need_des
  [29] LP_CPU_SLP_STALL_EN rw — need_des
  [28:21] LP_CPU_SLP_STALL_WAIT rw — need_des
  [20] LP_CPU_SLP_STALL_FLAG_EN rw — need_des
  [19] LP_CPU_SLP_WAITI_FLAG_EN rw — need_des
  [18] LP_CPU_FORCE_STALL rw — need_des
  [1] LP_CPU_STALL_RDY ro — need_des
  [0] LP_CPU_WAITI_RDY ro — need_des
0x188 LP_CPU_PWR1 wo — need_des
  [31] LP_CPU_SLEEP_REQ
0x18C LP_CPU_PWR2 — need_des
  [30:0] LP_CPU_WAKEUP_EN
0x190 LP_CPU_PWR3 ro — need_des
  [30:0] LP_CPU_WAKEUP_CAUSE
0x194 LP_CPU_PWR4 — need_des
  [30:0] LP_CPU_REJECT_EN
0x198 LP_CPU_PWR5 ro — need_des
  [30:0] LP_CPU_REJECT_CAUSE
0x19C HP_LP_CPU_COMM wo — need_des
  [31] HP_TRIGGER_LP — need_des
  [30] LP_TRIGGER_HP — need_des
0x1A0 HP_REGULATOR_CFG — need_des
  [31] DIG_REGULATOR_EN_CAL
0x1A4 MAIN_STATE access per field reset 0x2100801 — need_des
  [31:25] PMU_MAIN_CUR_ST_STATE ro — need_des
  [24:18] PMU_MAIN_TAR_ST_STATE ro — need_des
  [17:11] PMU_MAIN_LAST_ST_STATE ro — need_des
  [0] ENABLE_CALI_PMU_CNTL rw — need_des
0x1A8 PWR_STATE ro reset 0x802000 — need_des
  [31:23] PMU_HP_PWR_ST_STATE — need_des
  [22:18] PMU_LP_PWR_ST_STATE — need_des
  [17:13] PMU_BACKUP_ST_STATE — need_des
0x1AC CLK_STATE0 ro reset 0x80004000 — need_des
  [31] PMU_ANA_XPD_XTAL_STATE — need_des
  [30:27] PMU_ANA_XPD_PLL_STATE — need_des
  [25] PMU_ANA_I2C_RETENTION_STATE — need_des
  [24] PMU_ANA_I2C_ISO_EN_STATE — need_des
  [23:20] PMU_ICG_GLOBAL_PLL_STATE — need_des
  [19] PMU_ICG_GLOBAL_XTAL_STATE — need_des
  [18] PMU_ICG_SLP_SEL_STATE — need_des
  [17:16] PMU_ICG_MODEM_CODE_STATE — need_des
  [15] PMU_ICG_MODEM_SWITCH_STATE — need_des
  [14] PMU_ICG_SYS_CLK_EN_STATE — need_des
  [13] PMU_SYS_CLK_NO_DIV_STATE — need_des
  [12:11] PMU_SYS_CLK_SEL_STATE — need_des
  [10] PMU_SYS_CLK_SLP_SEL_STATE — need_des
  [6:4] PMU_ANA_XPD_PLL_I2C_STATE — need_des
  [3] STABLE_XPD_XTAL_STATE — need_des
  [2:0] STABLE_XPD_PLL_STATE — need_des
0x1B0 CLK_STATE1 ro reset 0xFFFFFFFF — need_des
  [31:0] PMU_ICG_FUNC_EN_STATE
0x1B4 CLK_STATE2 ro reset 0xFFFFFFFF — need_des
  [31:0] PMU_ICG_APB_EN_STATE
0x1B8 EXT_LDO_P0_0P1A access per field reset 0x40200100 — need_des
  [31] _0P1A_LDO_CNT_PRESCALER_SEL_0 rw — need_des
  [30:23] _0P1A_TARGET0_0 rw — need_des
  [22:15] _0P1A_TARGET1_0 rw — need_des
  [14] _0P1A_TIEH_0 rw — need_des
  [13] _0P1A_TIEH_NEG_EN_0 rw — need_des
  [12] _0P1A_TIEH_POS_EN_0 rw — need_des
  [11:9] _0P1A_TIEH_SEL_0 rw — need_des
  [8] _0P1A_XPD_0 rw — need_des
  [7] _0P1A_FORCE_TIEH_SEL_0 rw — need_des
  [6] _0P1A_CNT_CLR_0 wo — need_des
0x1BC EXT_LDO_P0_0P1A_ANA reset 0xB1000000 — need_des
  [31:28] ANA_0P1A_DREF_0 — need_des
  [27] ANA_0P1A_EN_CUR_LIM_0 — need_des
  [26] ANA_0P1A_EN_VDET_0 — need_des
  [25:23] ANA_0P1A_MUL_0 — need_des
0x1C0 EXT_LDO_P0_0P2A access per field reset 0x40200000 — need_des
  [31] _0P2A_LDO_CNT_PRESCALER_SEL_0 rw — need_des
  [30:23] _0P2A_TARGET0_0 rw — need_des
  [22:15] _0P2A_TARGET1_0 rw — need_des
  [14] _0P2A_TIEH_0 rw — need_des
  [13] _0P2A_TIEH_NEG_EN_0 rw — need_des
  [12] _0P2A_TIEH_POS_EN_0 rw — need_des
  [11:9] _0P2A_TIEH_SEL_0 rw — need_des
  [8] _0P2A_XPD_0 rw — need_des
  [7] _0P2A_FORCE_TIEH_SEL_0 rw — need_des
  [6] _0P2A_CNT_CLR_0 wo — need_des
0x1C4 EXT_LDO_P0_0P2A_ANA reset 0xA0000000 — need_des
  [31:28] ANA_0P2A_DREF_0 — need_des
  [27] ANA_0P2A_EN_CUR_LIM_0 — need_des
  [26] ANA_0P2A_EN_VDET_0 — need_des
  [25:23] ANA_0P2A_MUL_0 — need_des
0x1C8 EXT_LDO_P0_0P3A access per field reset 0x40200000 — need_des
  [31] _0P3A_LDO_CNT_PRESCALER_SEL_0 rw — need_des
  [30:23] _0P3A_TARGET0_0 rw — need_des
  [22:15] _0P3A_TARGET1_0 rw — need_des
  [14] _0P3A_TIEH_0 rw — need_des
  [13] _0P3A_TIEH_NEG_EN_0 rw — need_des
  [12] _0P3A_TIEH_POS_EN_0 rw — need_des
  [11:9] _0P3A_TIEH_SEL_0 rw — need_des
  [8] _0P3A_XPD_0 rw — need_des
  [7] _0P3A_FORCE_TIEH_SEL_0 rw — need_des
  [6] _0P3A_CNT_CLR_0 wo — need_des
0x1CC EXT_LDO_P0_0P3A_ANA reset 0xA0000000 — need_des
  [31:28] ANA_0P3A_DREF_0 — need_des
  [27] ANA_0P3A_EN_CUR_LIM_0 — need_des
  [26] ANA_0P3A_EN_VDET_0 — need_des
  [25:23] ANA_0P3A_MUL_0 — need_des
{0x1C8+8i} EXT_LDO_P1_0P{i}A access per field reset 0x40200000 (i=1..3) — need_des
  [31] _0P{i}A_LDO_CNT_PRESCALER_SEL_1 rw — need_des
  [30:23] _0P{i}A_TARGET0_1 rw — need_des
  [22:15] _0P{i}A_TARGET1_1 rw — need_des
  [14] _0P{i}A_TIEH_1 rw — need_des
  [13] _0P{i}A_TIEH_NEG_EN_1 rw — need_des
  [12] _0P{i}A_TIEH_POS_EN_1 rw — need_des
  [11:9] _0P{i}A_TIEH_SEL_1 rw — need_des
  [8] _0P{i}A_XPD_1 rw — need_des
  [7] _0P{i}A_FORCE_TIEH_SEL_1 rw — need_des
  [6] _0P{i}A_CNT_CLR_1 wo — need_des
{0x1CC+8i} EXT_LDO_P1_0P{i}A_ANA reset 0xA0000000 (i=1..3) — need_des
  [31:28] ANA_0P{i}A_DREF_1 — need_des
  [27] ANA_0P{i}A_EN_CUR_LIM_1 — need_des
  [26] ANA_0P{i}A_EN_VDET_1 — need_des
  [25:23] ANA_0P{i}A_MUL_1 — need_des
0x1E8 EXT_WAKEUP_LV — need_des
0x1EC EXT_WAKEUP_SEL — need_des
0x1F0 EXT_WAKEUP_ST ro — need_des
  [31:0] EXT_WAKEUP_STATUS
0x1F4 EXT_WAKEUP_CNTL — need_des
  [31] EXT_WAKEUP_FILTER — need_des
  [30] EXT_WAKEUP_STATUS_CLR — need_des
0x1F8 SDIO_WAKEUP_CNTL reset 0x3FF — need_des
  [9:0] SDIO_ACT_DNUM
0x1FC XTAL_SLP reset 0xF0000 — need_des
  [31:16] CNT_TARGET
0x200 CPU_SW_STALL — need_des
  [31:24] HPCORE0_SW_STALL_CODE — need_des
  [23:16] HPCORE1_SW_STALL_CODE — need_des
0x204 DCM_CTRL access per field reset 0x10000 — need_des
  [29] DCDC_EN_AMUX_TEST rw — Enable analog mux to pull PAD TEST_DCDC voltage signal
  [23:16] DCM_CUR_ST ro — need_des
  [15] DCDC_DS_FORCE_PD rw — need_des
  [14] DCDC_DS_FORCE_PU rw — need_des
  [13] DCDC_LS_FORCE_PD rw — need_des
  [12] DCDC_LS_FORCE_PU rw — need_des
  [11] DCDC_FB_RES_FORCE_PD rw — need_des
  [10] DCDC_FB_RES_FORCE_PU rw — need_des
  [9] DCDC_ON_FORCE_PD rw — need_des
  [8] DCDC_ON_FORCE_PU rw — need_des
  [7] DCDC_DONE_FORCE rw — need_des
  [3] DCDC_DEEPSLP_REQ wo — SW trigger dcdc enter deepsleep
  [2] DCDC_LIGHTSLP_REQ wo — SW trigger dcdc enter lightsleep
  [1] DCDC_OFF_REQ wo — SW trigger dcdc off
  [0] DCDC_ON_REQ wo — SW trigger dcdc on
0x208 DCM_WAIT_DELAY reset 0x4B0205 — need_des
  [25:16] DCDC_STABLE_DELAY
  [15:8] DCDC_RES_OFF_DELAY — DCDC fb res off delay
  [7:0] DCDC_PRE_DELAY — DCDC pre-on/post off delay
0x20C VDDBAT_CFG access per field — need_des
  [31] VDDBAT_SW_UPDATE wo — need_des
  [1:0] ANA_VDDBAT_MODE ro — need_des
0x210 TOUCH_PWR_CNTL reset 0x190140 — need_des
  [31] TOUCH_SLEEP_TIMER_EN — need_des
  [30] TOUCH_FORCE_DONE — need_des
  [29:14] TOUCH_SLEEP_CYCLES — need_des
  [13:5] TOUCH_WAIT_CYCLES — need_des
0x214 RDN_ECO access per field — need_des
  [31] PMU_RDN_ECO_EN rw — need_des
  [0] PMU_RDN_ECO_RESULT ro — need_des
0x218 POWER_PD_HP_CPU_CNTL reset 0x1C — need_des
  [5] FORCE_HP_CPU_PD — need_des
  [4] FORCE_HP_CPU_NO_ISO — need_des
  [3] FORCE_HP_CPU_NO_RESET — need_des
  [2] FORCE_HP_CPU_PU — need_des
  [1] FORCE_HP_CPU_ISO — need_des
  [0] FORCE_HP_CPU_RESET — need_des
0x21C POWER_PD_HP_CPU_MASK — need_des
  [31:27] PD_HP_CPU_MASK — need_des
  [4:0] XPD_HP_CPU_MASK — need_des
0x3FC DATE reset 0x2501030 — need_des
  [31] CLK_EN — need_des
  [30:0] PMU_DATE — need_des
